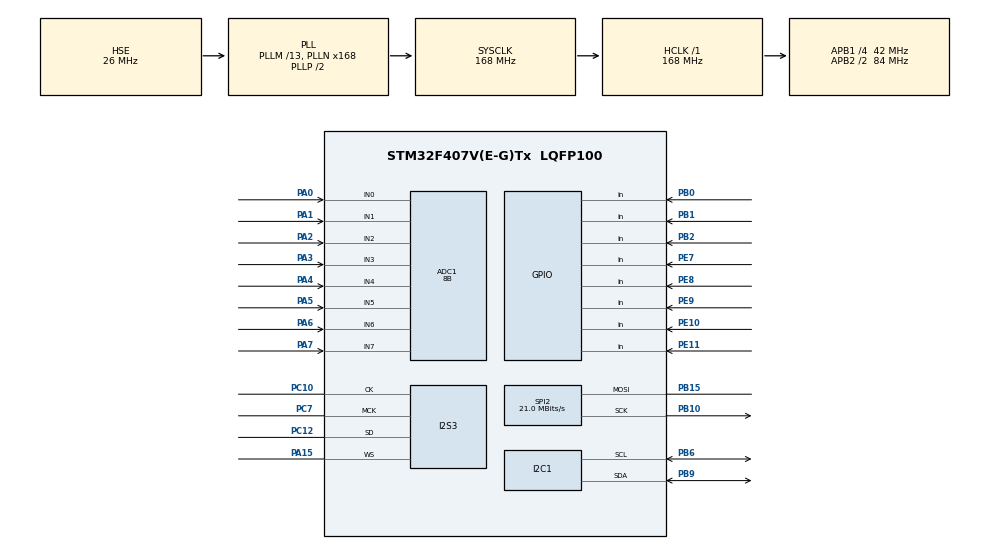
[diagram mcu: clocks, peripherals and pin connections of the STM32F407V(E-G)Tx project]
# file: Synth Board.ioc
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ADC1.Channel-0\#ChannelRegularConversion=ADC_CHANNEL_0
ADC1.Channel-1\#ChannelRegularConversion=ADC_CHANNEL_1
ADC1.Channel-2\#ChannelRegularConversion=ADC_CHANNEL_2
ADC1.Channel-3\#ChannelRegularConversion=ADC_CHANNEL_3
ADC1.Channel-4\#ChannelRegularConversion=ADC_CHANNEL_4
ADC1.Channel-5\#ChannelRegularConversion=ADC_CHANNEL_5
ADC1.Channel-6\#ChannelRegularConversion=ADC_CHANNEL_6
ADC1.Channel-7\#ChannelRegularConversion=ADC_CHANNEL_7
ADC1.ClockPrescaler=ADC_CLOCK_SYNC_PCLK_DIV8
ADC1.ContinuousConvMode=ENABLE
ADC1.DMAContinuousRequests=ENABLE
ADC1.EOCSelection=ADC_EOC_SINGLE_CONV
ADC1.ExternalTrigConv=ADC_SOFTWARE_START
ADC1.InjNumberOfConversion=0
ADC1.NbrOfConversion=8
ADC1.NbrOfConversionFlag=1
ADC1.Rank-0\#ChannelRegularConversion=1
ADC1.Rank-1\#ChannelRegularConversion=2
ADC1.Rank-2\#ChannelRegularConversion=3
ADC1.Rank-3\#ChannelRegularConversion=4
ADC1.Rank-4\#ChannelRegularConversion=5
ADC1.Rank-5\#ChannelRegularConversion=6
ADC1.Rank-6\#ChannelRegularConversion=7
ADC1.Rank-7\#ChannelRegularConversion=8
ADC1.Resolution=ADC_RESOLUTION_8B
ADC1.SamplingTime-0\#ChannelRegularConversion=ADC_SAMPLETIME_480CYCLES
ADC1.SamplingTime-1\#ChannelRegularConversion=ADC_SAMPLETIME_480CYCLES
ADC1.SamplingTime-2\#ChannelRegularConversion=ADC_SAMPLETIME_480CYCLES
ADC1.SamplingTime-3\#ChannelRegularConversion=ADC_SAMPLETIME_480CYCLES
ADC1.SamplingTime-4\#ChannelRegularConversion=ADC_SAMPLETIME_480CYCLES
ADC1.SamplingTime-5\#ChannelRegularConversion=ADC_SAMPLETIME_480CYCLES
ADC1.SamplingTime-6\#ChannelRegularConversion=ADC_SAMPLETIME_480CYCLES
ADC1.SamplingTime-7\#ChannelRegularConversion=ADC_SAMPLETIME_480CYCLES
ADC1.ScanConvMode=ENABLE
ADC1.master=1
Dma.ADC1.2.Direction=DMA_PERIPH_TO_MEMORY
Dma.ADC1.2.FIFOMode=DMA_FIFOMODE_DISABLE
Dma.ADC1.2.Instance=DMA2_Stream0
Dma.ADC1.2.MemDataAlignment=DMA_MDATAALIGN_BYTE
Dma.ADC1.2.MemInc=DMA_MINC_ENABLE
Dma.ADC1.2.Mode=DMA_CIRCULAR
Dma.ADC1.2.PeriphDataAlignment=DMA_PDATAALIGN_BYTE
Dma.ADC1.2.PeriphInc=DMA_PINC_DISABLE
Dma.ADC1.2.Priority=DMA_PRIORITY_LOW
Dma.Request0=SPI3_TX
Dma.Request1=SPI2_TX
Dma.Request2=ADC1
Dma.SPI2_TX.1.Direction=DMA_MEMORY_TO_PERIPH
Dma.SPI2_TX.1.FIFOMode=DMA_FIFOMODE_DISABLE
Dma.SPI2_TX.1.Instance=DMA1_Stream4
Dma.SPI2_TX.1.MemDataAlignment=DMA_MDATAALIGN_BYTE
Dma.SPI2_TX.1.MemInc=DMA_MINC_ENABLE
Dma.SPI2_TX.1.Mode=DMA_NORMAL
Dma.SPI2_TX.1.PeriphDataAlignment=DMA_PDATAALIGN_BYTE
Dma.SPI2_TX.1.PeriphInc=DMA_PINC_DISABLE
Dma.SPI2_TX.1.Priority=DMA_PRIORITY_LOW
Dma.SPI3_TX.0.Direction=DMA_MEMORY_TO_PERIPH
Dma.SPI3_TX.0.FIFOMode=DMA_FIFOMODE_ENABLE
Dma.SPI3_TX.0.FIFOThreshold=DMA_FIFO_THRESHOLD_FULL
Dma.SPI3_TX.0.Instance=DMA1_Stream7
Dma.SPI3_TX.0.MemBurst=DMA_MBURST_SINGLE
Dma.SPI3_TX.0.MemDataAlignment=DMA_MDATAALIGN_HALFWORD
Dma.SPI3_TX.0.MemInc=DMA_MINC_ENABLE
Dma.SPI3_TX.0.Mode=DMA_CIRCULAR
Dma.SPI3_TX.0.PeriphBurst=DMA_PBURST_SINGLE
Dma.SPI3_TX.0.PeriphDataAlignment=DMA_PDATAALIGN_HALFWORD
Dma.SPI3_TX.0.PeriphInc=DMA_PINC_DISABLE
Dma.SPI3_TX.0.Priority=DMA_PRIORITY_VERY_HIGH
I2C1.I2C_Mode=I2C_Fast
I2S3.AudioFreq=I2S_AUDIOFREQ_32K
I2S3.ErrorAudioFreq=-0.12 %
I2S3.FullDuplexMode=I2S_FULLDUPLEXMODE_DISABLE
I2S3.Instance=SPI$Index
I2S3.RealAudioFreq=31.96 KHz
I2S3.VirtualMode=I2S_MODE_MASTER
Mcu.Family=STM32F4
Mcu.Name=STM32F407V(E-G)Tx
Mcu.Package=LQFP100
NVIC.DMA1_Stream4_IRQn=true\:0\:0\:false\:false\:true\:false\:true\:true
NVIC.DMA1_Stream7_IRQn=true\:0\:0\:false\:false\:true\:false\:true\:true
NVIC.DMA2_Stream0_IRQn=true\:0\:0\:false\:false\:true\:false\:true\:true
NVIC.PriorityGroup=NVIC_PRIORITYGROUP_0
PA0-WKUP.Signal=ADCx_IN0
PA1.Signal=ADCx_IN1
PA15.Mode=Half_Duplex_Master
PA15.Signal=I2S3_WS
PA2.Signal=ADCx_IN2
PA3.Signal=ADCx_IN3
PA4.Signal=ADCx_IN4
PA5.Signal=ADCx_IN5
PA6.Signal=ADCx_IN6
PA7.Signal=ADCx_IN7
PB0.GPIO_PuPd=GPIO_PULLUP
PB0.Signal=GPIO_Input
PB1.GPIO_PuPd=GPIO_PULLUP
PB1.Signal=GPIO_Input
PB10.Mode=Simplex_Bidirectional_Master
PB10.Signal=SPI2_SCK
PB15.Mode=Simplex_Bidirectional_Master
PB15.Signal=SPI2_MOSI
PB2.GPIO_PuPd=GPIO_PULLUP
PB2.Signal=GPIO_Input
PB6.Mode=I2C
PB6.Signal=I2C1_SCL
PB9.Mode=I2C
PB9.Signal=I2C1_SDA
PC10.Mode=Half_Duplex_Master
PC10.Signal=I2S3_CK
PC12.Mode=Half_Duplex_Master
PC12.Signal=I2S3_SD
PC7.Mode=Master_Clock_Activated
PC7.Signal=I2S3_MCK
PE10.GPIO_PuPd=GPIO_PULLDOWN
PE10.Signal=GPIO_Input
PE11.GPIO_PuPd=GPIO_PULLDOWN
PE11.Signal=GPIO_Input
PE7.GPIO_PuPd=GPIO_PULLUP
PE7.Signal=GPIO_Input
PE8.GPIO_PuPd=GPIO_PULLDOWN
PE8.Signal=GPIO_Input
PE9.GPIO_PuPd=GPIO_PULLDOWN
PE9.Signal=GPIO_Input
PH0-OSC_IN.Mode=HSE-External-Oscillator
PH0-OSC_IN.Signal=RCC_OSC_IN
PH1-OSC_OUT.Mode=HSE-External-Oscillator
PH1-OSC_OUT.Signal=RCC_OSC_OUT
ProjectManager.HeapSize=0x200
ProjectManager.StackSize=0x400
ProjectManager.TargetToolchain=STM32CubeIDE
RCC.48MHZClocksFreq_Value=48000000
RCC.AHBFreq_Value=168000000
RCC.APB1CLKDivider=RCC_HCLK_DIV4
RCC.APB1Freq_Value=42000000
RCC.APB1TimFreq_Value=84000000
RCC.APB2CLKDivider=RCC_HCLK_DIV2
RCC.APB2Freq_Value=84000000
RCC.APB2TimFreq_Value=168000000
RCC.CortexFreq_Value=168000000
RCC.HCLKFreq_Value=168000000
RCC.HSE_VALUE=26000000
RCC.HSI_VALUE=16000000
RCC.LSE_VALUE=32768
RCC.PLLI2SN=90
RCC.PLLM=13
RCC.PLLN=168
RCC.PLLQ=7
RCC.PLLSourceVirtual=RCC_PLLSOURCE_HSE
RCC.SYSCLKFreq_VALUE=168000000
RCC.SYSCLKSource=RCC_SYSCLKSOURCE_PLLCLK
RCC.VCOOutputFreq_Value=336000000
SH.ADCx_IN0.0=ADC1_IN0,IN0
SH.ADCx_IN1.0=ADC1_IN1,IN1
SH.ADCx_IN2.0=ADC1_IN2,IN2
SH.ADCx_IN3.0=ADC1_IN3,IN3
SH.ADCx_IN4.0=ADC1_IN4,IN4
SH.ADCx_IN5.0=ADC1_IN5,IN5
SH.ADCx_IN6.0=ADC1_IN6,IN6
SH.ADCx_IN7.0=ADC1_IN7,IN7
SPI2.BaudRatePrescaler=SPI_BAUDRATEPRESCALER_2
SPI2.CalculateBaudRate=21.0 MBits/s
SPI2.Direction=SPI_DIRECTION_1LINE
SPI2.Mode=SPI_MODE_MASTER
SPI2.VirtualType=VM_MASTER
board=STM32F407G-DISC1

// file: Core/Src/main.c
/* USER CODE BEGIN Header */
/**
 ******************************************************************************
 * @file           : main.c
 * @brief          : Main program body
 ******************************************************************************
 * @attention
 *
 * Copyright (c) 2024 STMicroelectronics.
 * All rights reserved.
 *
 * This software is licensed under terms that can be found in the LICENSE file
 * in the root directory of this software component.
 * If no LICENSE file comes with this software, it is provided AS-IS.
 *
 ******************************************************************************
 */
/* USER CODE END Header */
#include "main.h"

/* USER CODE BEGIN Includes */
#include "event_loop.hpp"
/* USER CODE END Includes */

ADC_HandleTypeDef hadc1;
DMA_HandleTypeDef hdma_adc1;

I2C_HandleTypeDef hi2c1;

I2S_HandleTypeDef hi2s3;
DMA_HandleTypeDef hdma_spi3_tx;

SPI_HandleTypeDef hspi2;
DMA_HandleTypeDef hdma_spi2_tx;

void SystemClock_Config(void);
static void MX_GPIO_Init(void);
static void MX_DMA_Init(void);
static void MX_I2C1_Init(void);
static void MX_I2S3_Init(void);
static void MX_SPI2_Init(void);
static void MX_ADC1_Init(void);

int main(void)
{

  /* MCU Configuration--------------------------------------------------------*/

  /* Reset of all peripherals, Initializes the Flash interface and the Systick. */
  HAL_Init();

  /* Configure the system clock */
  SystemClock_Config();

  /* Initialize all configured peripherals */
  MX_GPIO_Init();
  MX_DMA_Init();
  MX_I2C1_Init();
  MX_I2S3_Init();
  MX_SPI2_Init();
  MX_ADC1_Init();

  /* Infinite loop */
  /* USER CODE BEGIN WHILE */
	EventLoopC();
	while (1) {
    /* USER CODE END WHILE */

	}
}

void SystemClock_Config(void)
{
  RCC_OscInitTypeDef RCC_OscInitStruct = {0};
  RCC_ClkInitTypeDef RCC_ClkInitStruct = {0};

  /** Configure the main internal regulator output voltage
  */
  __HAL_RCC_PWR_CLK_ENABLE();
  __HAL_PWR_VOLTAGESCALING_CONFIG(PWR_REGULATOR_VOLTAGE_SCALE1);

  /** Initializes the RCC Oscillators according to the specified parameters
  * in the RCC_OscInitTypeDef structure.
  */
  RCC_OscInitStruct.OscillatorType = RCC_OSCILLATORTYPE_HSE;
  RCC_OscInitStruct.HSEState = RCC_HSE_ON;
  RCC_OscInitStruct.PLL.PLLState = RCC_PLL_ON;
  RCC_OscInitStruct.PLL.PLLSource = RCC_PLLSOURCE_HSE;
  RCC_OscInitStruct.PLL.PLLM = 13;
  RCC_OscInitStruct.PLL.PLLN = 168;
  RCC_OscInitStruct.PLL.PLLP = RCC_PLLP_DIV2;
  RCC_OscInitStruct.PLL.PLLQ = 7;
  if (HAL_RCC_OscConfig(&RCC_OscInitStruct) != HAL_OK)
  {
    Error_Handler();
  }

  /** Initializes the CPU, AHB and APB buses clocks
  */
  RCC_ClkInitStruct.ClockType = RCC_CLOCKTYPE_HCLK|RCC_CLOCKTYPE_SYSCLK
                              |RCC_CLOCKTYPE_PCLK1|RCC_CLOCKTYPE_PCLK2;
  RCC_ClkInitStruct.SYSCLKSource = RCC_SYSCLKSOURCE_PLLCLK;
  RCC_ClkInitStruct.AHBCLKDivider = RCC_SYSCLK_DIV1;
  RCC_ClkInitStruct.APB1CLKDivider = RCC_HCLK_DIV4;
  RCC_ClkInitStruct.APB2CLKDivider = RCC_HCLK_DIV2;

  if (HAL_RCC_ClockConfig(&RCC_ClkInitStruct, FLASH_LATENCY_5) != HAL_OK)
  {
    Error_Handler();
  }
}

static void MX_ADC1_Init(void)
{

  ADC_ChannelConfTypeDef sConfig = {0};

  /** Configure the global features of the ADC (Clock, Resolution, Data Alignment and number of conversion)
  */
  hadc1.Instance = ADC1;
  hadc1.Init.ClockPrescaler = ADC_CLOCK_SYNC_PCLK_DIV8;
  hadc1.Init.Resolution = ADC_RESOLUTION_8B;
  hadc1.Init.ScanConvMode = ENABLE;
  hadc1.Init.ContinuousConvMode = ENABLE;
  hadc1.Init.DiscontinuousConvMode = DISABLE;
  hadc1.Init.ExternalTrigConvEdge = ADC_EXTERNALTRIGCONVEDGE_NONE;
  hadc1.Init.ExternalTrigConv = ADC_SOFTWARE_START;
  hadc1.Init.DataAlign = ADC_DATAALIGN_RIGHT;
  hadc1.Init.NbrOfConversion = 8;
  hadc1.Init.DMAContinuousRequests = ENABLE;
  hadc1.Init.EOCSelection = ADC_EOC_SINGLE_CONV;
  if (HAL_ADC_Init(&hadc1) != HAL_OK)
  {
    Error_Handler();
  }

  /** Configure for the selected ADC regular channel its corresponding rank in the sequencer and its sample time.
  */
  sConfig.Channel = ADC_CHANNEL_0;
  sConfig.Rank = 1;
  sConfig.SamplingTime = ADC_SAMPLETIME_480CYCLES;
  if (HAL_ADC_ConfigChannel(&hadc1, &sConfig) != HAL_OK)
  {
    Error_Handler();
  }

  /** Configure for the selected ADC regular channel its corresponding rank in the sequencer and its sample time.
  */
  sConfig.Channel = ADC_CHANNEL_1;
  sConfig.Rank = 2;
  if (HAL_ADC_ConfigChannel(&hadc1, &sConfig) != HAL_OK)
  {
    Error_Handler();
  }

  /** Configure for the selected ADC regular channel its corresponding rank in the sequencer and its sample time.
  */
  sConfig.Channel = ADC_CHANNEL_2;
  sConfig.Rank = 3;
  if (HAL_ADC_ConfigChannel(&hadc1, &sConfig) != HAL_OK)
  {
    Error_Handler();
  }

  /** Configure for the selected ADC regular channel its corresponding rank in the sequencer and its sample time.
  */
  sConfig.Channel = ADC_CHANNEL_3;
  sConfig.Rank = 4;
  if (HAL_ADC_ConfigChannel(&hadc1, &sConfig) != HAL_OK)
  {
    Error_Handler();
  }

  /** Configure for the selected ADC regular channel its corresponding rank in the sequencer and its sample time.
  */
  sConfig.Channel = ADC_CHANNEL_4;
  sConfig.Rank = 5;
  if (HAL_ADC_ConfigChannel(&hadc1, &sConfig) != HAL_OK)
  {
    Error_Handler();
  }

  /** Configure for the selected ADC regular channel its corresponding rank in the sequencer and its sample time.
  */
  sConfig.Channel = ADC_CHANNEL_5;
  sConfig.Rank = 6;
  if (HAL_ADC_ConfigChannel(&hadc1, &sConfig) != HAL_OK)
  {
    Error_Handler();
  }

  /** Configure for the selected ADC regular channel its corresponding rank in the sequencer and its sample time.
  */
  sConfig.Channel = ADC_CHANNEL_6;
  sConfig.Rank = 7;
  if (HAL_ADC_ConfigChannel(&hadc1, &sConfig) != HAL_OK)
  {
    Error_Handler();
  }

  /** Configure for the selected ADC regular channel its corresponding rank in the sequencer and its sample time.
  */
  sConfig.Channel = ADC_CHANNEL_7;
  sConfig.Rank = 8;
  if (HAL_ADC_ConfigChannel(&hadc1, &sConfig) != HAL_OK)
  {
    Error_Handler();
  }

}

static void MX_I2C1_Init(void)
{

  hi2c1.Instance = I2C1;
  hi2c1.Init.ClockSpeed = 400000;
  hi2c1.Init.DutyCycle = I2C_DUTYCYCLE_2;
  hi2c1.Init.OwnAddress1 = 0;
  hi2c1.Init.AddressingMode = I2C_ADDRESSINGMODE_7BIT;
  hi2c1.Init.DualAddressMode = I2C_DUALADDRESS_DISABLE;
  hi2c1.Init.OwnAddress2 = 0;
  hi2c1.Init.GeneralCallMode = I2C_GENERALCALL_DISABLE;
  hi2c1.Init.NoStretchMode = I2C_NOSTRETCH_DISABLE;
  if (HAL_I2C_Init(&hi2c1) != HAL_OK)
  {
    Error_Handler();
  }

}

static void MX_I2S3_Init(void)
{

  hi2s3.Instance = SPI3;
  hi2s3.Init.Mode = I2S_MODE_MASTER_TX;
  hi2s3.Init.Standard = I2S_STANDARD_PHILIPS;
  hi2s3.Init.DataFormat = I2S_DATAFORMAT_16B;
  hi2s3.Init.MCLKOutput = I2S_MCLKOUTPUT_ENABLE;
  hi2s3.Init.AudioFreq = I2S_AUDIOFREQ_32K;
  hi2s3.Init.CPOL = I2S_CPOL_LOW;
  hi2s3.Init.ClockSource = I2S_CLOCK_PLL;
  hi2s3.Init.FullDuplexMode = I2S_FULLDUPLEXMODE_DISABLE;
  if (HAL_I2S_Init(&hi2s3) != HAL_OK)
  {
    Error_Handler();
  }

}

static void MX_SPI2_Init(void)
{

  /* SPI2 parameter configuration*/
  hspi2.Instance = SPI2;
  hspi2.Init.Mode = SPI_MODE_MASTER;
  hspi2.Init.Direction = SPI_DIRECTION_1LINE;
  hspi2.Init.DataSize = SPI_DATASIZE_8BIT;
  hspi2.Init.CLKPolarity = SPI_POLARITY_LOW;
  hspi2.Init.CLKPhase = SPI_PHASE_1EDGE;
  hspi2.Init.NSS = SPI_NSS_SOFT;
  hspi2.Init.BaudRatePrescaler = SPI_BAUDRATEPRESCALER_2;
  hspi2.Init.FirstBit = SPI_FIRSTBIT_MSB;
  hspi2.Init.TIMode = SPI_TIMODE_DISABLE;
  hspi2.Init.CRCCalculation = SPI_CRCCALCULATION_DISABLE;
  hspi2.Init.CRCPolynomial = 10;
  if (HAL_SPI_Init(&hspi2) != HAL_OK)
  {
    Error_Handler();
  }

}

static void MX_DMA_Init(void)
{

  /* DMA controller clock enable */
  __HAL_RCC_DMA1_CLK_ENABLE();
  __HAL_RCC_DMA2_CLK_ENABLE();

  /* DMA interrupt init */
  /* DMA1_Stream4_IRQn interrupt configuration */
  HAL_NVIC_SetPriority(DMA1_Stream4_IRQn, 0, 0);
  HAL_NVIC_EnableIRQ(DMA1_Stream4_IRQn);
  /* DMA1_Stream7_IRQn interrupt configuration */
  HAL_NVIC_SetPriority(DMA1_Stream7_IRQn, 0, 0);
  HAL_NVIC_EnableIRQ(DMA1_Stream7_IRQn);
  /* DMA2_Stream0_IRQn interrupt configuration */
  HAL_NVIC_SetPriority(DMA2_Stream0_IRQn, 0, 0);
  HAL_NVIC_EnableIRQ(DMA2_Stream0_IRQn);

}

static void MX_GPIO_Init(void)
{
  GPIO_InitTypeDef GPIO_InitStruct = {0};

  /* GPIO Ports Clock Enable */
  __HAL_RCC_GPIOH_CLK_ENABLE();
  __HAL_RCC_GPIOA_CLK_ENABLE();
  __HAL_RCC_GPIOB_CLK_ENABLE();
  __HAL_RCC_GPIOE_CLK_ENABLE();
  __HAL_RCC_GPIOC_CLK_ENABLE();

  /*Configure GPIO pins : PB0 PB1 PB2 */
  GPIO_InitStruct.Pin = GPIO_PIN_0|GPIO_PIN_1|GPIO_PIN_2;
  GPIO_InitStruct.Mode = GPIO_MODE_INPUT;
  GPIO_InitStruct.Pull = GPIO_PULLUP;
  HAL_GPIO_Init(GPIOB, &GPIO_InitStruct);

  /*Configure GPIO pin : PE7 */
  GPIO_InitStruct.Pin = GPIO_PIN_7;
  GPIO_InitStruct.Mode = GPIO_MODE_INPUT;
  GPIO_InitStruct.Pull = GPIO_PULLUP;
  HAL_GPIO_Init(GPIOE, &GPIO_InitStruct);

  /*Configure GPIO pins : PE8 PE9 PE10 PE11 */
  GPIO_InitStruct.Pin = GPIO_PIN_8|GPIO_PIN_9|GPIO_PIN_10|GPIO_PIN_11;
  GPIO_InitStruct.Mode = GPIO_MODE_INPUT;
  GPIO_InitStruct.Pull = GPIO_PULLDOWN;
  HAL_GPIO_Init(GPIOE, &GPIO_InitStruct);

}

void Error_Handler(void)
{
	__disable_irq();
	while (1) {
	}
}
